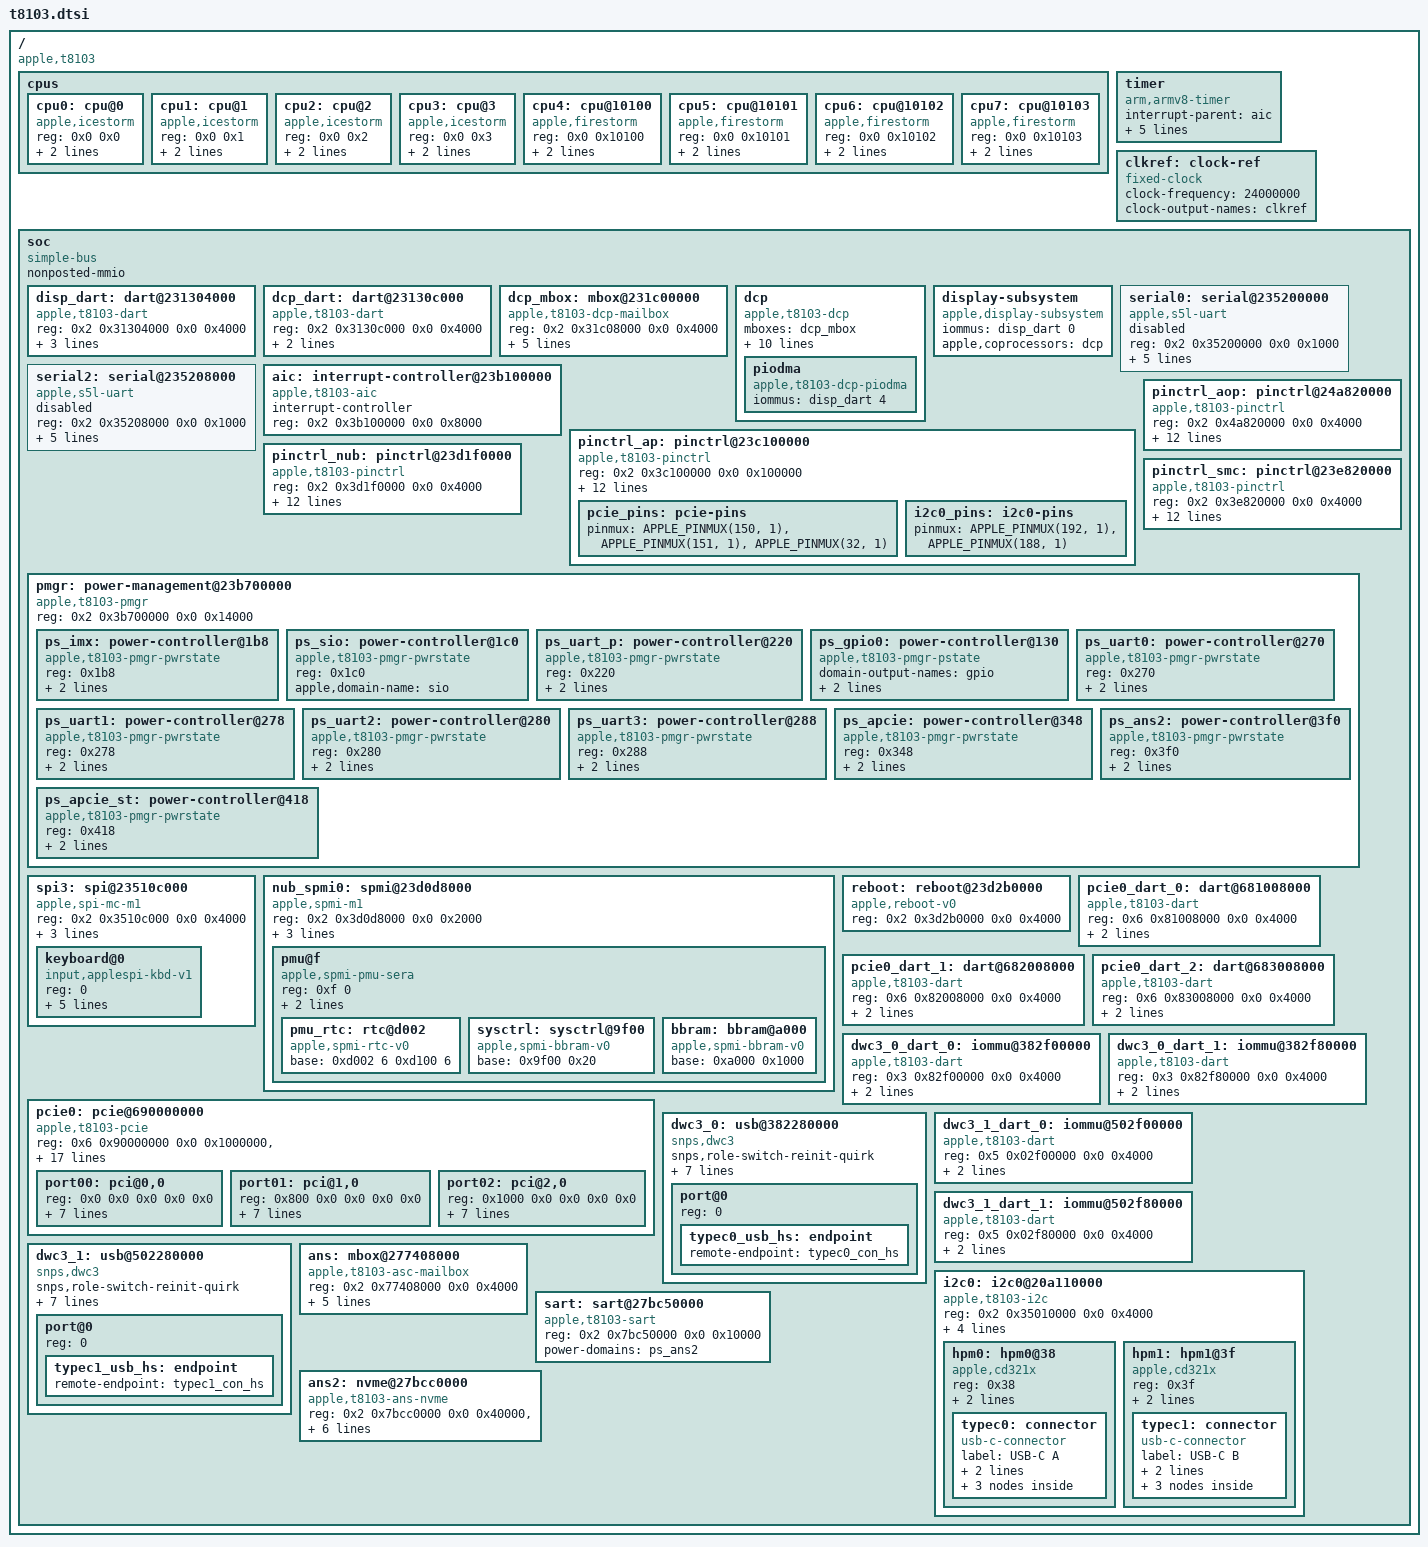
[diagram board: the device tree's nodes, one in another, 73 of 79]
// SPDX-License-Identifier: GPL-2.0+ OR MIT
/*
 * Apple T8103 "M1" SoC
 *
 * Other names: H13G, "Tonga"
 *
 * Copyright The Asahi Linux Contributors
 */

#include <dt-bindings/gpio/gpio.h>
#include <dt-bindings/interrupt-controller/apple-aic.h>
#include <dt-bindings/interrupt-controller/irq.h>
#include <dt-bindings/pinctrl/apple.h>

#define APPLE_CLK_GPIO     0x130
#define APPLE_CLK_SIOBUSIF 0x1c0
#define APPLE_CLK_SIO      0x1c8
#define APPLE_CLK_SPI_P    0x218
#define APPLE_CLK_UART_P   0x220
#define APPLE_CLK_SPI3     0x258
#define APPLE_CLK_UART0    0x270

#define APPLE_CLK_NUB_GPIO 0x80

/ {
	compatible = "apple,t8103", "apple,arm-platform";

	#address-cells = <2>;
	#size-cells = <2>;

	cpus {
		#address-cells = <2>;
		#size-cells = <0>;

		cpu0: cpu@0 {
			compatible = "apple,icestorm";
			device_type = "cpu";
			reg = <0x0 0x0>;
			enable-method = "spin-table";
			cpu-release-addr = <0 0>; /* To be filled by loader */
		};

		cpu1: cpu@1 {
			compatible = "apple,icestorm";
			device_type = "cpu";
			reg = <0x0 0x1>;
			enable-method = "spin-table";
			cpu-release-addr = <0 0>; /* To be filled by loader */
		};

		cpu2: cpu@2 {
			compatible = "apple,icestorm";
			device_type = "cpu";
			reg = <0x0 0x2>;
			enable-method = "spin-table";
			cpu-release-addr = <0 0>; /* To be filled by loader */
		};

		cpu3: cpu@3 {
			compatible = "apple,icestorm";
			device_type = "cpu";
			reg = <0x0 0x3>;
			enable-method = "spin-table";
			cpu-release-addr = <0 0>; /* To be filled by loader */
		};

		cpu4: cpu@10100 {
			compatible = "apple,firestorm";
			device_type = "cpu";
			reg = <0x0 0x10100>;
			enable-method = "spin-table";
			cpu-release-addr = <0 0>; /* To be filled by loader */
		};

		cpu5: cpu@10101 {
			compatible = "apple,firestorm";
			device_type = "cpu";
			reg = <0x0 0x10101>;
			enable-method = "spin-table";
			cpu-release-addr = <0 0>; /* To be filled by loader */
		};

		cpu6: cpu@10102 {
			compatible = "apple,firestorm";
			device_type = "cpu";
			reg = <0x0 0x10102>;
			enable-method = "spin-table";
			cpu-release-addr = <0 0>; /* To be filled by loader */
		};

		cpu7: cpu@10103 {
			compatible = "apple,firestorm";
			device_type = "cpu";
			reg = <0x0 0x10103>;
			enable-method = "spin-table";
			cpu-release-addr = <0 0>; /* To be filled by loader */
		};
	};

	timer {
		compatible = "arm,armv8-timer";
		interrupt-parent = <&aic>;
		interrupt-names = "phys", "virt", "hyp-phys", "hyp-virt";
		interrupts = <AIC_FIQ AIC_TMR_GUEST_PHYS IRQ_TYPE_LEVEL_HIGH>,
			     <AIC_FIQ AIC_TMR_GUEST_VIRT IRQ_TYPE_LEVEL_HIGH>,
			     <AIC_FIQ AIC_TMR_HV_PHYS IRQ_TYPE_LEVEL_HIGH>,
			     <AIC_FIQ AIC_TMR_HV_VIRT IRQ_TYPE_LEVEL_HIGH>;
	};

	clkref: clock-ref {
		compatible = "fixed-clock";
		#clock-cells = <0>;
		clock-frequency = <24000000>;
		clock-output-names = "clkref";
	};

	soc {
		compatible = "simple-bus";
		#address-cells = <2>;
		#size-cells = <2>;

		ranges;
		nonposted-mmio;

		disp_dart: dart@231304000 {
			compatible = "apple,t8103-dart";
			reg = <0x2 0x31304000 0x0 0x4000>;
			#iommu-cells = <1>;
			interrupt-parent = <&aic>;
			interrupts = <AIC_IRQ 445 IRQ_TYPE_LEVEL_HIGH>;
			apple,force-locked;
		};

		dcp_dart: dart@23130c000 {
			compatible = "apple,t8103-dart";
			reg = <0x2 0x3130c000 0x0 0x4000>;
			#iommu-cells = <1>;
			interrupt-parent = <&aic>;
			interrupts = <AIC_IRQ 445 IRQ_TYPE_LEVEL_HIGH>;
		};

		dcp_mbox: mbox@231c00000 {
			compatible = "apple,t8103-dcp-mailbox",
				"apple,t8103-asc-mailbox";
			reg = <0x2 0x31c08000 0x0 0x4000>;
			interrupt-parent = <&aic>;
			interrupts = <AIC_IRQ 427 IRQ_TYPE_LEVEL_HIGH>,
				<AIC_IRQ 428 IRQ_TYPE_LEVEL_HIGH>,
				<AIC_IRQ 429 IRQ_TYPE_LEVEL_HIGH>,
				<AIC_IRQ 430 IRQ_TYPE_LEVEL_HIGH>;
			interrupt-names = "send-empty", "send-not-empty",
				"recv-empty", "recv-not-empty";
			#mbox-cells = <0>;
		};

		dcp: dcp {
			compatible = "apple,t8103-dcp";
			mboxes = <&dcp_mbox>;
			mbox-names = "mbox";
			iommus = <&dcp_dart 0>;

			reg-names = "coproc", "disp-0", "disp-1", "disp-2",
				"disp-3", "disp-4", "disp-5", "doorbell";
			reg = <0x2 0x31c00000 0x0 0x4000>,
				<0x2 0x30000000 0x0 0x3e8000>,
				<0x2 0x31320000 0x0 0x4000>,
				<0x2 0x31344000 0x0 0x4000>,
				<0x2 0x31800000 0x0 0x800000>,
				<0x2 0x3b3d0000 0x0 0x4000>,
				<0x2 0x3b738000 0x0 0x1000>,
				<0x2 0x3bc3c000 0x0 0x1000>;

			piodma: piodma {
				compatible = "apple,t8103-dcp-piodma";
				iommus = <&disp_dart 4>;
			};
		};

		display-subsystem {
			compatible = "apple,display-subsystem";
			iommus = <&disp_dart 0>;
			apple,coprocessors = <&dcp>;
		};

		serial0: serial@235200000 {
			compatible = "apple,s5l-uart";
			reg = <0x2 0x35200000 0x0 0x1000>;
			reg-io-width = <4>;
			interrupt-parent = <&aic>;
			interrupts = <AIC_IRQ 605 IRQ_TYPE_LEVEL_HIGH>;
			clocks = <&clkref>, <&clkref>, <&clkref>;
			clock-names = "uart", "clk_uart_baud0", "clk_uart_baud1";
			power-domains = <&ps_uart0>;
			status = "disabled";
		};

		serial2: serial@235208000 {
			compatible = "apple,s5l-uart";
			reg = <0x2 0x35208000 0x0 0x1000>;
			reg-io-width = <4>;
			interrupt-parent = <&aic>;
			interrupts = <AIC_IRQ 607 IRQ_TYPE_LEVEL_HIGH>;
			clocks = <&clkref>, <&clkref>, <&clkref>;
			clock-names = "uart", "clk_uart_baud0", "clk_uart_baud1";
			power-domains = <&ps_uart2>;
			status = "disabled";
		};

		aic: interrupt-controller@23b100000 {
			compatible = "apple,t8103-aic", "apple,aic";
			#interrupt-cells = <3>;
			interrupt-controller;
			reg = <0x2 0x3b100000 0x0 0x8000>;
		};

		pinctrl_ap: pinctrl@23c100000 {
			compatible = "apple,t8103-pinctrl", "apple,pinctrl";
			reg = <0x2 0x3c100000 0x0 0x100000>;

			gpio-controller;
			#gpio-cells = <2>;
			gpio-ranges = <&pinctrl_ap 0 0 212>;
			apple,npins = <212>;

			interrupt-controller;
			interrupt-parent = <&aic>;
			interrupts = <AIC_IRQ 190 IRQ_TYPE_LEVEL_HIGH>,
				     <AIC_IRQ 191 IRQ_TYPE_LEVEL_HIGH>,
				     <AIC_IRQ 192 IRQ_TYPE_LEVEL_HIGH>,
				     <AIC_IRQ 193 IRQ_TYPE_LEVEL_HIGH>,
				     <AIC_IRQ 194 IRQ_TYPE_LEVEL_HIGH>,
				     <AIC_IRQ 195 IRQ_TYPE_LEVEL_HIGH>,
				     <AIC_IRQ 196 IRQ_TYPE_LEVEL_HIGH>;

			pcie_pins: pcie-pins {
				pinmux = <APPLE_PINMUX(150, 1)>,
					 <APPLE_PINMUX(151, 1)>,
					 <APPLE_PINMUX(32, 1)>;
			};

			i2c0_pins: i2c0-pins {
				pinmux = <APPLE_PINMUX(192, 1)>,
					 <APPLE_PINMUX(188, 1)>;
			};
		};

		pinctrl_aop: pinctrl@24a820000 {
			compatible = "apple,t8103-pinctrl", "apple,pinctrl";
			reg = <0x2 0x4a820000 0x0 0x4000>;

			gpio-controller;
			#gpio-cells = <2>;
			gpio-ranges = <&pinctrl_aop 0 0 42>;
			apple,npins = <42>;

			interrupt-controller;
			interrupt-parent = <&aic>;
			interrupts = <AIC_IRQ 268 IRQ_TYPE_LEVEL_HIGH>,
				     <AIC_IRQ 269 IRQ_TYPE_LEVEL_HIGH>,
				     <AIC_IRQ 270 IRQ_TYPE_LEVEL_HIGH>,
				     <AIC_IRQ 271 IRQ_TYPE_LEVEL_HIGH>,
				     <AIC_IRQ 272 IRQ_TYPE_LEVEL_HIGH>,
				     <AIC_IRQ 273 IRQ_TYPE_LEVEL_HIGH>,
				     <AIC_IRQ 274 IRQ_TYPE_LEVEL_HIGH>;
		};

		pinctrl_nub: pinctrl@23d1f0000 {
			compatible = "apple,t8103-pinctrl", "apple,pinctrl";
			reg = <0x2 0x3d1f0000 0x0 0x4000>;

			gpio-controller;
			#gpio-cells = <2>;
			gpio-ranges = <&pinctrl_nub 0 0 23>;
			apple,npins = <23>;

			interrupt-controller;
			interrupt-parent = <&aic>;
			interrupts = <AIC_IRQ 330 IRQ_TYPE_LEVEL_HIGH>,
				     <AIC_IRQ 331 IRQ_TYPE_LEVEL_HIGH>,
				     <AIC_IRQ 332 IRQ_TYPE_LEVEL_HIGH>,
				     <AIC_IRQ 333 IRQ_TYPE_LEVEL_HIGH>,
				     <AIC_IRQ 334 IRQ_TYPE_LEVEL_HIGH>,
				     <AIC_IRQ 335 IRQ_TYPE_LEVEL_HIGH>,
				     <AIC_IRQ 336 IRQ_TYPE_LEVEL_HIGH>;
		};

		pinctrl_smc: pinctrl@23e820000 {
			compatible = "apple,t8103-pinctrl", "apple,pinctrl";
			reg = <0x2 0x3e820000 0x0 0x4000>;

			gpio-controller;
			#gpio-cells = <2>;
			gpio-ranges = <&pinctrl_smc 0 0 16>;
			apple,npins = <16>;

			interrupt-controller;
			interrupt-parent = <&aic>;
			interrupts = <AIC_IRQ 391 IRQ_TYPE_LEVEL_HIGH>,
				     <AIC_IRQ 392 IRQ_TYPE_LEVEL_HIGH>,
				     <AIC_IRQ 393 IRQ_TYPE_LEVEL_HIGH>,
				     <AIC_IRQ 394 IRQ_TYPE_LEVEL_HIGH>,
				     <AIC_IRQ 395 IRQ_TYPE_LEVEL_HIGH>,
				     <AIC_IRQ 396 IRQ_TYPE_LEVEL_HIGH>,
				     <AIC_IRQ 397 IRQ_TYPE_LEVEL_HIGH>;
		};

		pmgr: power-management@23b700000 {
			compatible = "apple,t8103-pmgr", "apple,pmgr", "syscon", "simple-mfd";
			#address-cells = <1>;
			#size-cells = <0>;

			reg = <0x2 0x3b700000 0x0 0x14000>;

			ps_imx: power-controller@1b8 {
				compatible = "apple,t8103-pmgr-pwrstate", "apple,pmgr-pwrstate";
				reg = <0x1b8>;
				#power-domain-cells = <0>;
				#reset-cells = <0>;
				apple,domain-name = "imx";
				apple,always-on;
			};

			ps_sio: power-controller@1c0 {
				compatible = "apple,t8103-pmgr-pwrstate", "apple,pmgr-pwrstate";
				reg = <0x1c0>;
				#power-domain-cells = <0>;
				#reset-cells = <0>;
				apple,domain-name = "sio";
			};

			ps_uart_p: power-controller@220 {
				compatible = "apple,t8103-pmgr-pwrstate", "apple,pmgr-pwrstate";
				reg = <0x220>;
				#power-domain-cells = <0>;
				#reset-cells = <0>;
				apple,domain-name = "uart_p";
				power-domains = <&ps_sio>;
			};

			ps_gpio0: power-controller@130 {
				domain-output-names = "gpio";
				compatible = "apple,t8103-pmgr-pstate", "apple,pmgr-pstate";
				reg = <0x130>;
				#power-domain-cells = <0>;
				power-domains = <&ps_sio>;
			};

			ps_uart0: power-controller@270 {
				compatible = "apple,t8103-pmgr-pwrstate", "apple,pmgr-pwrstate";
				reg = <0x270>;
				#power-domain-cells = <0>;
				#reset-cells = <0>;
				apple,domain-name = "uart0";
				power-domains = <&ps_uart_p>;
			};

			ps_uart1: power-controller@278 {
				compatible = "apple,t8103-pmgr-pwrstate", "apple,pmgr-pwrstate";
				reg = <0x278>;
				#power-domain-cells = <0>;
				#reset-cells = <0>;
				apple,domain-name = "uart1";
				power-domains = <&ps_uart_p>;
			};

			ps_uart2: power-controller@280 {
				compatible = "apple,t8103-pmgr-pwrstate", "apple,pmgr-pwrstate";
				reg = <0x280>;
				#power-domain-cells = <0>;
				#reset-cells = <0>;
				apple,domain-name = "uart2";
				power-domains = <&ps_uart_p>;
			};

			ps_uart3: power-controller@288 {
				compatible = "apple,t8103-pmgr-pwrstate", "apple,pmgr-pwrstate";
				reg = <0x288>;
				#power-domain-cells = <0>;
				#reset-cells = <0>;
				apple,domain-name = "uart3";
				power-domains = <&ps_uart_p>;
			};

			ps_apcie: power-controller@348 {
				compatible = "apple,t8103-pmgr-pwrstate", "apple,pmgr-pwrstate";
				reg = <0x348>;
				#power-domain-cells = <0>;
				#reset-cells = <0>;
				apple,domain-name = "apcie";
				power-domains = <&ps_imx>;
			};

			ps_ans2: power-controller@3f0 {
				compatible = "apple,t8103-pmgr-pwrstate", "apple,pmgr-pwrstate";
				reg = <0x3f0>;
				#power-domain-cells = <0>;
				#reset-cells = <0>;
				apple,domain-name = "ans2";
				power-domains = <&ps_apcie_st>;
			};

			ps_apcie_st: power-controller@418 {
				compatible = "apple,t8103-pmgr-pwrstate", "apple,pmgr-pwrstate";
				reg = <0x418>;
				#power-domain-cells = <0>;
				#reset-cells = <0>;
				apple,domain-name = "apcie_st";
				power-domains = <&ps_apcie>;
			};
		};

		spi3: spi@23510c000 {
			compatible = "apple,spi-mc-m1";
			reg = <0x2 0x3510c000 0x0 0x4000>;
			interrupt-parent = <&aic>;
			interrupts = <0 617 4>;
			cs-gpios = <&pinctrl_ap 49 0>;
			#address-cells = <1>;
			#size-cells = <0>;

			keyboard@0 {
				compatible = "input,applespi-kbd-v1";
				reg = <0>;
				spi-max-frequency = <2000000>;
				spien-gpios = <&pinctrl_ap 195 0>;
				irq-gpios = <&pinctrl_nub 13 0>;
				interrupt-parent = <&pinctrl_nub>;
				interrupts = <13 8>;
			};
		};

		nub_spmi0: spmi@23d0d8000 {
			compatible = "apple,spmi-m1";
			reg = <0x2 0x3d0d8000 0x0 0x2000>;
			interrupts = <0 343 4>;

			#address-cells = <2>;
			#size-cells = <0>;
			interrupt-controller;
			#interrupt-cells = <2>;
			interrupt-parent = <&aic>;

			pmu@f {
				compatible = "apple,spmi-pmu-sera", "apple,spmi-pmu";
				reg = <0xf 0>;
				interrupt-parent = <&nub_spmi0>;
				interrupts = <2 0>;

				pmu_rtc: rtc@d002 {
					compatible = "apple,spmi-rtc-v0";
					base = <0xd002 6   0xd100 6>;
				};

				sysctrl: sysctrl@9f00 {
					compatible = "apple,spmi-bbram-v0";
					base = <0x9f00 0x20>;
				};

				bbram: bbram@a000 {
					compatible = "apple,spmi-bbram-v0";
					base = <0xa000 0x1000>;
				};
			};
		};

		reboot: reboot@23d2b0000 {
			compatible = "apple,reboot-v0";
			reg = <0x2 0x3d2b0000 0x0 0x4000>;
		};

		pcie0_dart_0: dart@681008000 {
			compatible = "apple,t8103-dart";
			reg = <0x6 0x81008000 0x0 0x4000>;
			#iommu-cells = <1>;
			interrupt-parent = <&aic>;
			interrupts = <AIC_IRQ 696 IRQ_TYPE_LEVEL_HIGH>;
		};

		pcie0_dart_1: dart@682008000 {
			compatible = "apple,t8103-dart";
			reg = <0x6 0x82008000 0x0 0x4000>;
			#iommu-cells = <1>;
			interrupt-parent = <&aic>;
			interrupts = <AIC_IRQ 699 IRQ_TYPE_LEVEL_HIGH>;
		};

		pcie0_dart_2: dart@683008000 {
			compatible = "apple,t8103-dart";
			reg = <0x6 0x83008000 0x0 0x4000>;
			#iommu-cells = <1>;
			interrupt-parent = <&aic>;
			interrupts = <AIC_IRQ 702 IRQ_TYPE_LEVEL_HIGH>;
		};

		pcie0: pcie@690000000 {
			compatible = "apple,t8103-pcie", "apple,pcie";
			device_type = "pci";

			reg = <0x6 0x90000000 0x0 0x1000000>,
			      <0x6 0x80000000 0x0 0x100000>,
			      <0x6 0x81000000 0x0 0x8000>,
			      <0x6 0x82000000 0x0 0x8000>,
			      <0x6 0x83000000 0x0 0x8000>;
			reg-names = "config", "rc", "port0", "port1", "port2";

			interrupt-parent = <&aic>;
			interrupts = <AIC_IRQ 695 IRQ_TYPE_LEVEL_HIGH>,
				     <AIC_IRQ 698 IRQ_TYPE_LEVEL_HIGH>,
				     <AIC_IRQ 701 IRQ_TYPE_LEVEL_HIGH>;

			msi-controller;
			msi-parent = <&pcie0>;
			msi-ranges = <&aic AIC_IRQ 704 IRQ_TYPE_EDGE_RISING 32>;


			iommu-map = <0x100 &pcie0_dart_0 1 1>,
				    <0x200 &pcie0_dart_1 1 1>,
				    <0x300 &pcie0_dart_2 1 1>;
			iommu-map-mask = <0xff00>;

			bus-range = <0 3>;
			#address-cells = <3>;
			#size-cells = <2>;
			ranges = <0x43000000 0x6 0xa0000000 0x6 0xa0000000 0x0 0x20000000>,
				 <0x02000000 0x0 0xc0000000 0x6 0xc0000000 0x0 0x40000000>;

			pinctrl-0 = <&pcie_pins>;
			pinctrl-names = "default";

			port00: pci@0,0 {
				device_type = "pci";
				reg = <0x0 0x0 0x0 0x0 0x0>;
				reset-gpios = <&pinctrl_ap 152 GPIO_ACTIVE_LOW>;
				max-link-speed = <2>;

				#address-cells = <3>;
				#size-cells = <2>;
				ranges;

				interrupt-controller;
				#interrupt-cells = <1>;

				interrupt-map-mask = <0 0 0 7>;
				interrupt-map = <0 0 0 1 &port00 0 0 0 0>,
						<0 0 0 2 &port00 0 0 0 1>,
						<0 0 0 3 &port00 0 0 0 2>,
						<0 0 0 4 &port00 0 0 0 3>;
			};

			port01: pci@1,0 {
				device_type = "pci";
				reg = <0x800 0x0 0x0 0x0 0x0>;
				reset-gpios = <&pinctrl_ap 153 GPIO_ACTIVE_LOW>;
				max-link-speed = <2>;

				#address-cells = <3>;
				#size-cells = <2>;
				ranges;

				interrupt-controller;
				#interrupt-cells = <1>;

				interrupt-map-mask = <0 0 0 7>;
				interrupt-map = <0 0 0 1 &port01 0 0 0 0>,
						<0 0 0 2 &port01 0 0 0 1>,
						<0 0 0 3 &port01 0 0 0 2>,
						<0 0 0 4 &port01 0 0 0 3>;
			};

			port02: pci@2,0 {
				device_type = "pci";
				reg = <0x1000 0x0 0x0 0x0 0x0>;
				reset-gpios = <&pinctrl_ap 33 GPIO_ACTIVE_LOW>;
				max-link-speed = <1>;

				#address-cells = <3>;
				#size-cells = <2>;
				ranges;

				interrupt-controller;
				#interrupt-cells = <1>;

				interrupt-map-mask = <0 0 0 7>;
				interrupt-map = <0 0 0 1 &port02 0 0 0 0>,
						<0 0 0 2 &port02 0 0 0 1>,
						<0 0 0 3 &port02 0 0 0 2>,
						<0 0 0 4 &port02 0 0 0 3>;
			};
		};

		dwc3_0_dart_0: iommu@382f00000 {
			compatible = "apple,t8103-dart";
			reg = <0x3 0x82f00000 0x0 0x4000>;
			interrupt-parent = <&aic>;
			interrupts = <AIC_IRQ 781 IRQ_TYPE_LEVEL_HIGH>;
			#iommu-cells = <1>;
		};

		dwc3_0_dart_1: iommu@382f80000 {
			compatible = "apple,t8103-dart";
			reg = <0x3 0x82f80000 0x0 0x4000>;
			interrupt-parent = <&aic>;
			interrupts = <AIC_IRQ 781 IRQ_TYPE_LEVEL_HIGH>;
			#iommu-cells = <1>;
		};

		dwc3_0: usb@382280000{
			compatible = "snps,dwc3";
			snps,role-switch-reinit-quirk;
			reg = <0x3 0x82280000 0x0 0x100000>;
			interrupt-parent = <&aic>;
			interrupts = <AIC_IRQ 777 IRQ_TYPE_LEVEL_HIGH>;
			dr_mode = "otg";
			usb-role-switch;
			role-switch-default-mode = "host";
			iommus = <&dwc3_0_dart_0 0>, <&dwc3_0_dart_1 1>;
			#address-cells = <1>;
			#size-cells = <0>;

			port@0 {
				reg = <0>;
				typec0_usb_hs: endpoint {
					remote-endpoint = <&typec0_con_hs>;
				};
			};
		};

		dwc3_1_dart_0: iommu@502f00000 {
			compatible = "apple,t8103-dart";
			reg = <0x5 0x02f00000 0x0 0x4000>;
			interrupt-parent = <&aic>;
			interrupts = <AIC_IRQ 861 IRQ_TYPE_LEVEL_HIGH>;
			#iommu-cells = <1>;
		};

		dwc3_1_dart_1: iommu@502f80000 {
			compatible = "apple,t8103-dart";
			reg = <0x5 0x02f80000 0x0 0x4000>;
			interrupt-parent = <&aic>;
			interrupts = <AIC_IRQ 861 IRQ_TYPE_LEVEL_HIGH>;
			#iommu-cells = <1>;
		};

		dwc3_1: usb@502280000{
			compatible = "snps,dwc3";
			snps,role-switch-reinit-quirk;
			reg = <0x5 0x02280000 0x0 0x100000>;
			interrupt-parent = <&aic>;
			interrupts = <AIC_IRQ 857 IRQ_TYPE_LEVEL_HIGH>;
			dr_mode = "otg";
			usb-role-switch;
			role-switch-default-mode = "host";
			iommus = <&dwc3_1_dart_0 0>, <&dwc3_1_dart_1 1>;
			#address-cells = <1>;
			#size-cells = <0>;

			port@0 {
			reg = <0>;
				typec1_usb_hs: endpoint {
					remote-endpoint = <&typec1_con_hs>;
				};
			};
		};

		i2c0: i2c0@20a110000 {
			compatible = "apple,t8103-i2c";
			reg = <0x2 0x35010000 0x0 0x4000>;
			clocks = <&clkref>, <&clkref>;
			clock-names = "gate", "ref";
			interrupt-parent = <&aic>;
			interrupts = <0 627 4>;
			pinctrl-0 = <&i2c0_pins>;
			pinctrl-names = "default";
			#address-cells = <0x1>;
			#size-cells = <0x0>;

			hpm0: hpm0@38 {
				compatible = "apple,cd321x";
				reg = <0x38>;
				interrupt-parent = <&pinctrl_ap>;
				interrupts = <106 IRQ_TYPE_LEVEL_LOW>;
				interrupt-names = "irq";
				typec0: connector {
					compatible = "usb-c-connector";
					label = "USB-C A";
					power-role = "dual";
					data-role = "dual";

					ports {
						#address-cells = <1>;
						#size-cells = <0>;
						port@0 {
							reg = <0>;
							typec0_con_hs: endpoint {
								remote-endpoint = <&typec0_usb_hs>;
							};
						};
					};
				};
			};

			hpm1: hpm1@3f {
				compatible = "apple,cd321x";
				reg = <0x3f>;
				interrupt-parent = <&pinctrl_ap>;
				interrupts = <106 IRQ_TYPE_LEVEL_LOW>;
				interrupt-names = "irq";

				typec1: connector {
					compatible = "usb-c-connector";
					label = "USB-C B";
					power-role = "dual";
					data-role = "dual";

					ports {
						#address-cells = <1>;
						#size-cells = <0>;
						port@0 {
							reg = <0>;
							typec1_con_hs: endpoint {
								remote-endpoint = <&typec1_usb_hs>;
							};
						};
					};
				};
			};
		};

		ans: mbox@277408000 {
			compatible = "apple,t8103-asc-mailbox";
			reg = <0x2 0x77408000 0x0 0x4000>;
			interrupt-parent = <&aic>;
			interrupts = <AIC_IRQ 583 IRQ_TYPE_LEVEL_HIGH>,
				<AIC_IRQ 584 IRQ_TYPE_LEVEL_HIGH>,
				<AIC_IRQ 585 IRQ_TYPE_LEVEL_HIGH>,
				<AIC_IRQ 586 IRQ_TYPE_LEVEL_HIGH>;
			interrupt-names = "send-empty", "send-not-empty",
				"recv-empty", "recv-not-empty";
			#mbox-cells = <0>;
		};

		sart: sart@27bc50000 {
			compatible = "apple,t8103-sart";
			reg = <0x2 0x7bc50000 0x0 0x10000>;
			power-domains = <&ps_ans2>;
		};

		ans2: nvme@27bcc0000 {
			compatible = "apple,t8103-ans-nvme";
			reg = <0x2 0x7bcc0000 0x0 0x40000>, <0x2 0x77400000 0x0 0x4000>;
			reg-names = "nvme", "coproc";
			interrupt-parent = <&aic>;
			interrupts = <AIC_IRQ 590 IRQ_TYPE_LEVEL_HIGH>;
			mboxes = <&ans>;
			apple,sart = <&sart>;
			power-domains = <&ps_ans2>;
		 };
	};
};
